# rCSL_mcasp_001 register map
Vendor: Texas Instruments
Peripheral module from a debugger description file (folder c674x).
Registers are 32-bit, read-write, reset 0x0 unless marked. A register's access mark holds for its fields unless they carry their own. Offsets are as the file gives them; lines under a group give offsets from that group; [hi:lo] are bit positions; {n}, {i} and the like mark numbered series; 'fields as' and 'values as' point back to an identical list; <NAME> marks a mode.

## MCASP — MCASP is a serial port used for audio data transfer in different formats like I2S , SPDIF..
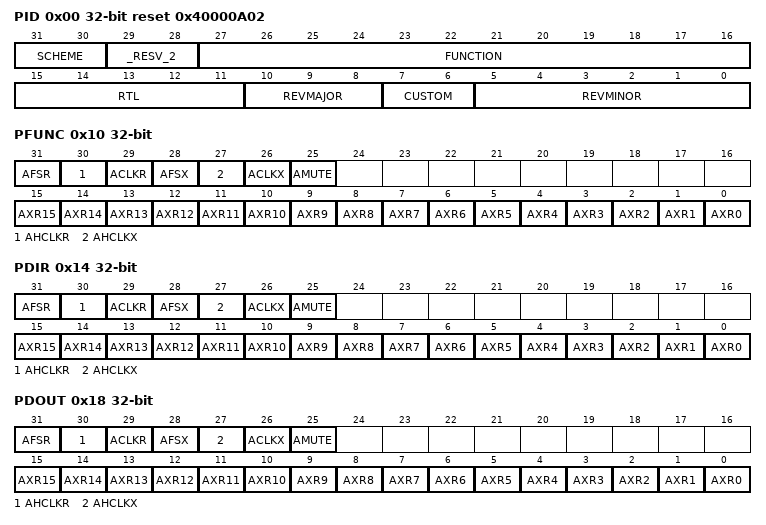
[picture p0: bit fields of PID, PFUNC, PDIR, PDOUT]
0x00 PID access not given reset 0x40000A02 (reset mask 0xF000FFFF)
  [31:30] SCHEME ro
  [29:28] _RESV_2 — (access N)
  [27:16] FUNCTION ro — McASP
  [15:11] RTL ro
  [10:8] REVMAJOR ro
  [7:6] CUSTOM ro — non-custom
  [5:0] REVMINOR ro
0x10 PFUNC access not given
  [all] fields
    0=MCASP; 1=GPIO
  [31] AFSR rw — AFSR PFUNC 31
  [30] AHCLKR rw — AHCLKR PFUNC 30
  [29] ACLKR rw — ACLKR PFUNC 29
  [28] AFSX rw — AFSX PFUNC 28
  [27] AHCLKX rw — AHCLKX PFUNC 27
  [26] ACLKX rw — ACLKX PFUNC 26
  [25] AMUTE rw — AMUTE PFUNC 25
  [n] AXR{n} rw (n=0..15) — AXR PFUNC BIT {n}
0x14 PDIR access not given
  [all] fields
    0=INPUT; 1=OUTPUT
  [31] AFSR rw — AFSR PDIR 31
  [30] AHCLKR rw — AHCLKR PDIR 30
  [29] ACLKR rw — ACLKR PDIR 29
  [28] AFSX rw — AFSX PDIR 28
  [27] AHCLKX rw — AHCLKX PDIR 27
  [26] ACLKX rw — ACLKX PDIR 26
  [25] AMUTE rw — AMUTE PDIR 25
  [n] AXR{n} rw (n=0..15) — AXR PDIR BIT {n}
0x18 PDOUT access not given
  [all] fields
    0=DRV0; 1=DRV1
  [31] AFSR rw — AFSR PDOUT 31
  [30] AHCLKR rw — AHCLKR PDOUT 30
  [29] ACLKR rw — ACLKR PDOUT 29
  [28] AFSX rw — AFSX PDOUT 28
  [27] AHCLKX rw — AHCLKX PDOUT 27
  [26] ACLKX rw — ACLKX PDOUT 26
  [25] AMUTE rw — AMUTE PDOUT 25
  [n] AXR{n} rw (n=0..15) — AXR PDOUT BIT {n}
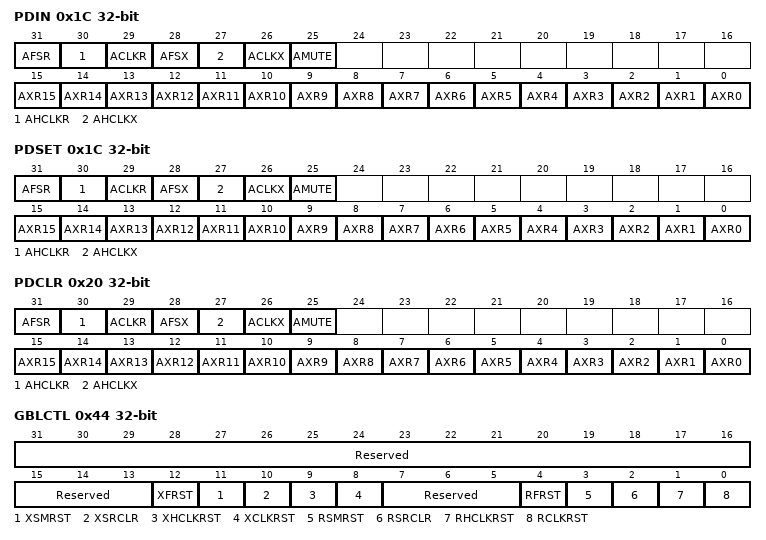
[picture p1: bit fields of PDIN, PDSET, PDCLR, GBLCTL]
0x1C PDIN access not given — The pin data input register (PDIN) holds the I/O pin state of each of the McASP pins. PDIN allows the actual value of the pin to be read, regardless of the state of PFUNC and PDIR.
  [all] fields
    0=LOW; 1=HIGH
  [31] AFSR rw — AFSR PDIN 31
  [30] AHCLKR rw — AHCLKR PDIN 30
  [29] ACLKR rw — ACLKR PDIN 29
  [28] AFSX rw — AFSX PDIN 28
  [27] AHCLKX rw — AHCLKX PDIN 27
  [26] ACLKX rw — ACLKX PDIN 26
  [25] AMUTE rw — AMUTE PDIN 25
  [n] AXR{n} rw (n=0..15) — AXR PDIN BIT {n}
0x1C PDSET access not given — The pin data set register (PDSET) is an alias of the pin data output register (PDOUT) for writes only. Writing a 1 to the PDSET bit sets the corresponding bit in PDOUT and, if PFUNC = 1 (GPIO function) and PDIR = 1 (output), drives a logic high on the pin.
  [all] fields
    0=NOEFFECT; 1=SET
  [31] AFSR rw — AFSR PDSET 31
  [30] AHCLKR rw — AHCLKR PDSET 30
  [29] ACLKR rw — ACLKR PDSET 29
  [28] AFSX rw — AFSX PDSET 28
  [27] AHCLKX rw — AHCLKX PDSET 27
  [26] ACLKX rw — ACLKX PDSET 26
  [25] AMUTE rw — AMUTE PDSET 25
  [n] AXR{n} rw (n=0..15) — AXR PDSET BIT {n}
0x20 PDCLR access not given — The pin data clear register (PDCLR) is an alias of the pin data output register (PDOUT) for writes only. Writing a 1 to the PDCLR bit clears the corresponding bit in PDOUT and, if PFUNC = 1 (GPIO function) and PDIR = 1 (output), drives a logic low on the pin.
  [all] fields
    0=NOEFFECT; 1=CLEAR
  [31] AFSR rw — AFSR PDCLR 31
  [30] AHCLKR rw — AHCLKR PDCLR 30
  [29] ACLKR rw — ACLKR PDCLR 29
  [28] AFSX rw — AFSX PDCLR 28
  [27] AHCLKX rw — AHCLKX PDCLR 27
  [26] ACLKX rw — ACLKX PDCLR 26
  [25] AMUTE rw — AMUTE PDCLR 25
  [n] AXR{n} rw (n=0..15) — AXR PDCLR BIT {n}
0x44 GBLCTL access not given
  [31:13] Reserved — (access N)
  [12] XFRST rw — Frame sync generator reset
    0=RESET; 1=ACTIVE
  [11] XSMRST rw — XMT state machine reset
    0=RESET; 1=ACTIVE
  [10] XSRCLR rw — XMT serializer clear
    0=CLEAR; 1=ACTIVE
  [9] XHCLKRST rw — XMT High Freq. clk Divider
    0=RESET; 1=ACTIVE
  [8] XCLKRST rw — XMT clock divder reset
    0=RESET; 1=ACTIVE
  [7:5] Reserved — (access N)
  [4] RFRST rw — Frame sync generator reset
    0=RESET; 1=ACTIVE
  [3] RSMRST rw — RCV state machine reset
    0=RESET; 1=ACTIVE
  [2] RSRCLR rw — RCV serializer clear
    0=CLEAR; 1=ACTIVE
  [1] RHCLKRST rw — RCV High Freq. clk Divider
    0=RESET; 1=ACTIVE
  [0] RCLKRST rw — RCV clock divder reset
    0=RESET; 1=ACTIVE
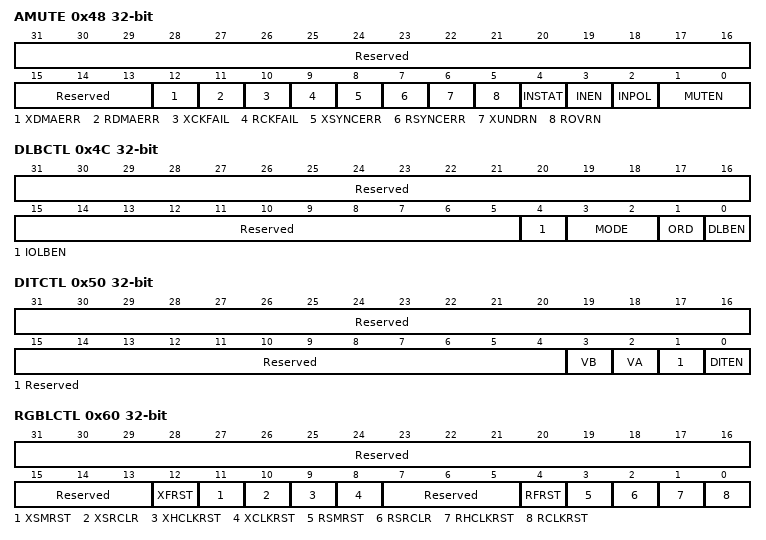
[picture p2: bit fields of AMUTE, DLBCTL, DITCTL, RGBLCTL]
0x48 AMUTE access not given
  [31:13] Reserved — (access N)
  [12] XDMAERR rw — MUTETXDMAERR occur
    0=DISABLE; 1=ENABLE
  [11] RDMAERR rw — MUTERXDMAERR occur
    0=DISABLE; 1=ENABLE
  [10] XCKFAIL rw — XMT bad clock
    0=DISABLE; 1=ENABLE
  [9] RCKFAIL rw — RCV bad clock
    0=DISABLE; 1=ENABLE
  [8] XSYNCERR rw — XMT unexpected FS
    0=DISABLE; 1=ENABLE
  [7] RSYNCERR rw — RCV unexpected FS
    0=DISABLE; 1=ENABLE
  [6] XUNDRN rw — XMT underrun occurs
    0=DISABLE; 1=ENABLE
  [5] ROVRN rw — RCV overun occurs
    0=DISABLE; 1=ENABLE
  [4] INSTAT ro — status of mute in pin
    0=INACTIVE; 1=ACTIVE
  [3] INEN rw — drive AMUTE active on mute in active
    0=DISABLE; 1=ENABLE
  [2] INPOL rw — Mute input polarity
    0=ACTHIGH; 1=ACTLOW
  [1:0] MUTEN rw — AMUTE pin enable
    0=DISABLE; 1=ERRHIGH; 2=ERRLOW
0x4C DLBCTL access not given
  [31:5] Reserved — (access N)
  [4] IOLBEN rw — IO loopback enable
    0=DISABLE; 1=ENABLE
  [3:2] MODE rw — Loop back clock source generator
    1=XMTCLK
  [1] ORD rw — Loopback order
    0=XMTODD; 1=XMTEVEN
  [0] DLBEN rw — Loop back mode
    0=DISABLE; 1=ENABLE
0x50 DITCTL access not given
  [31:4] Reserved — (access N)
  [3] VB rw — Valib bit for odd TDM
    0=ZERO; 1=ONE
  [2] VA rw — Valib bit for even TDM
    0=ZERO; 1=ONE
  [1] Reserved — (access N)
  [0] DITEN rw — XMT DIT Mode Enable
    0=DISABLE; 1=ENABLE
0x60 RGBLCTL access not given
  [31:13] Reserved — (access N)
  [12] XFRST ro — Frame sync generator reset
    0=RESET; 1=ACTIVE
  [11] XSMRST ro — XMT state machine reset
    0=RESET; 1=ACTIVE
  [10] XSRCLR ro — XMT serializer clear
    0=CLEAR; 1=ACTIVE
  [9] XHCLKRST ro — XMT High Freq. clk Divider
    0=RESET; 1=ACTIVE
  [8] XCLKRST ro — XMT clock divder reset
    0=RESET; 1=ACTIVE
  [7:5] Reserved — (access N)
  [4] RFRST rw — Frame sync generator reset
    0=RESET; 1=ACTIVE
  [3] RSMRST rw — RCV state machine reset
    0=RESET; 1=ACTIVE
  [2] RSRCLR rw — RCV serializer clear
    0=CLEAR; 1=ACTIVE
  [1] RHCLKRST rw — RCV High Freq. clk Divider
    0=RESET; 1=ACTIVE
  [0] RCLKRST rw — RCV clock divder reset
    0=RESET; 1=ACTIVE
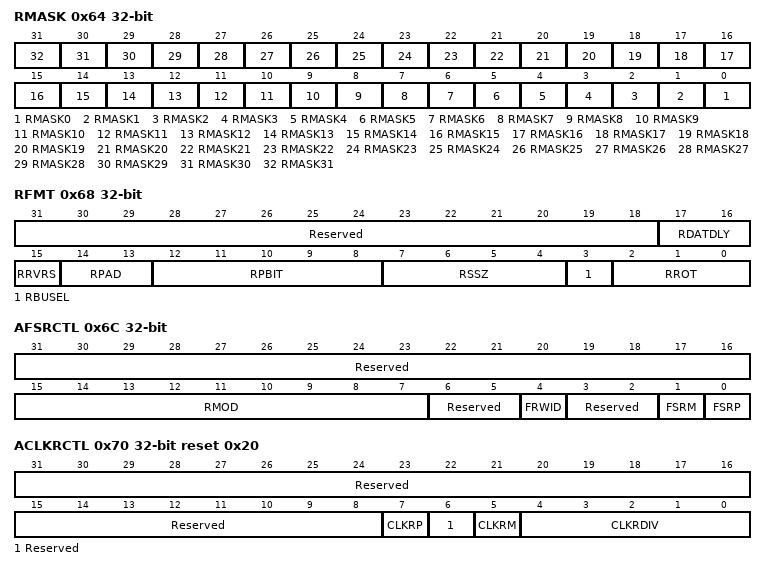
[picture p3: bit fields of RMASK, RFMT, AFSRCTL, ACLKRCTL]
0x64 RMASK
  [all] fields
    0=USEMASK; 1=NOMASK
  [n] RMASK{n} (n=0..31) — RMASK BIT {n}
0x68 RFMT access not given
  [31:18] Reserved — (access N)
  [17:16] RDATDLY rw — RCV Frame sync delay
    0=0BIT (0 Bit delay); 1=1BIT (1 Bit delay); 2=2BIT (2 Bit delay)
  [15] RRVRS rw — RCV serial stream bit order
    0=LSBFIRST; 1=MSBFIRST
  [14:13] RPAD rw — Pad value
    0=ZERO; 1=ONE; 2=RPBIT
  [12:8] RPBIT rw — Pad bit position
  [7:4] RSSZ rw — RCV slot Size
  [3] RBUSEL rw — Write to RBUF using CPU/DMA
    0=VBUSP (DMA port access); 1=VBUS (CPU port Access)
  [2:0] RROT rw — Right Rotate Value
    0=NONE; 1=4BITS; 2=8BITS; 3=12BITS; 4=16BITS; 5=20BITS; 6=24BITS; 7=28BITS
0x6C AFSRCTL access not given
  [31:16] Reserved — (access N)
  [15:7] RMOD rw — RCV Frame sync mode
    0=BURST; 2=I2S
  [6:5] Reserved — (access N)
  [4] FRWID rw — RCV Frame sync Duration
    0=BIT; 1=WORD
  [3:2] Reserved — (access N)
  [1] FSRM rw — RCV frame sync External
    0=EXTERNAL; 1=INTERNAL
  [0] FSRP rw — RCV Frame sync Polarity
    0=RISINGEDGE; 1=FALLINGEDGE
0x70 ACLKRCTL access not given reset 0x20
  [31:8] Reserved — (access N)
  [7] CLKRP rw — RCV Clock Polarity
    0=FALLINGEDGE; 1=RISINGEDGE
  [6] Reserved — (access N)
  [5] CLKRM rw — RCV clock source
    0=EXTERNAL; 1=INTERNAL
  [4:0] CLKRDIV rw — RCV clock devide ratio
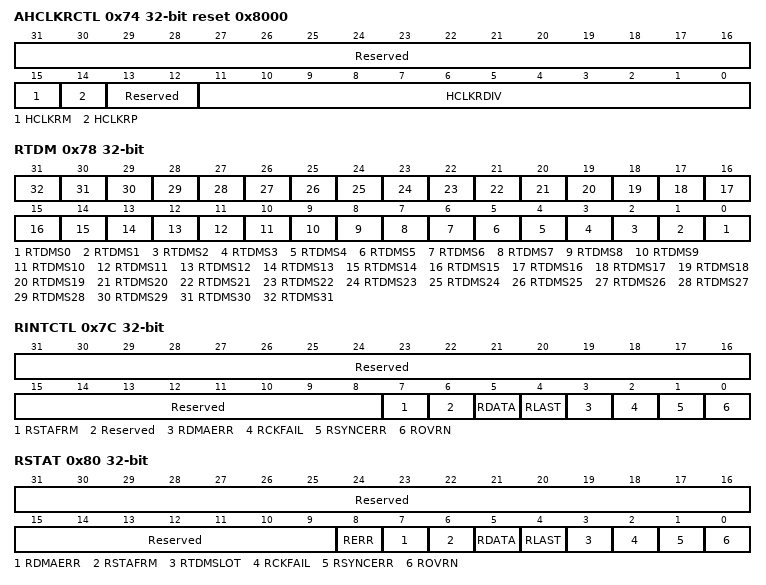
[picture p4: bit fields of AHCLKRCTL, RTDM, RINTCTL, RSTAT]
0x74 AHCLKRCTL access not given reset 0x8000
  [31:16] Reserved — (access N)
  [15] HCLKRM rw — High Freq. RCV clock Source
    0=EXTERNAL; 1=INTERNAL
  [14] HCLKRP rw — High Freq. clock Polarity Before diviser
    0=NOTINVERTED; 1=INVERTED
  [13:12] Reserved — (access N)
  [11:0] HCLKRDIV rw — RCV clock Divide Ratio
0x78 RTDM
  [all] fields
    0=INACTIVE; 1=ACTIVE
  [n] RTDMS{n} (n=0..31) — RCV mode during TDM time slot {n}
0x7C RINTCTL access not given
  [31:8] Reserved — (access N)
  [7] RSTAFRM rw — RCV Start of Frame Interrupt
    0=DISABLE; 1=ENABLE
  [6] Reserved — (access N)
  [5] RDATA rw — RCV Data Interrupt
    0=DISABLE; 1=ENABLE
  [4] RLAST rw — RCV Last Slot Interrupt
    0=DISABLE; 1=ENABLE
  [3] RDMAERR rw — RCV DMA Bus Error
    0=DISABLE; 1=ENABLE
  [2] RCKFAIL rw — Bad Clock Interrupt
    0=DISABLE; 1=ENABLE
  [1] RSYNCERR rw — RCV Unexpected FSR Interrupt
    0=DISABLE; 1=ENABLE
  [0] ROVRN rw — RCV Underrun Flag
    0=DISABLE; 1=ENABLE
0x80 RSTAT access not given
  [31:9] Reserved — (access N)
  [8] RERR — RCV Error
    0=NOERROR; 1=ERROR
  [7] RDMAERR rw — RCV DMA bus error
    0=NOERROR; 1=ERROR
  [6] RSTAFRM rw — Start of Frame-RCV
    0=NO; 1=YES
  [5] RDATA rw — Data Ready Flag
    0=NO; 1=YES
  [4] RLAST rw — Last Slot Interrupt Flag
    0=NO; 1=YES
  [3] RTDMSLOT rw — EvenOdd Slot
    0=ODD; 1=EVEN
  [2] RCKFAIL rw — Bad Transmit Flag
    0=NO; 1=YES
  [1] RSYNCERR rw — Unexpected RCV Frame sync flag
    0=NO; 1=YES
  [0] ROVRN rw — RCV Underrun Flag
    0=NO; 1=YES
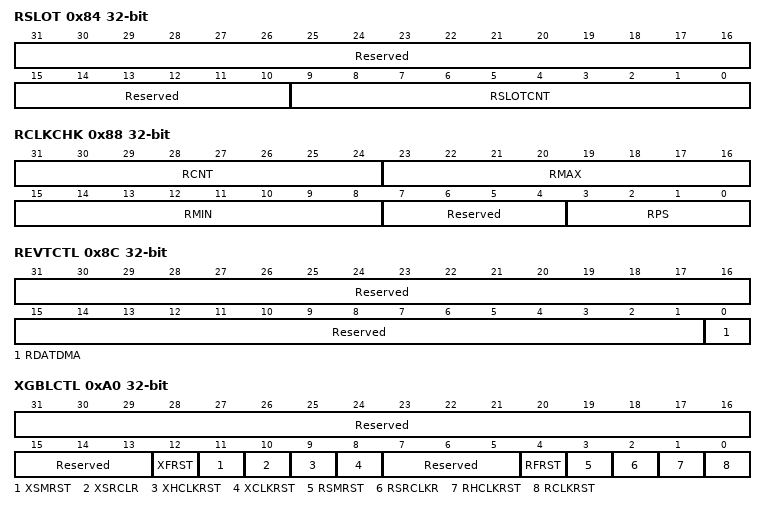
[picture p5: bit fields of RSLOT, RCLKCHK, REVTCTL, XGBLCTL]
0x84 RSLOT access not given
  [31:10] Reserved — (access N)
  [9:0] RSLOTCNT ro — Current RCV time slot count
0x88 RCLKCHK access not given
  [31:24] RCNT ro — RCV clock count value
  [23:16] RMAX rw — RCV clock maximum boundary
  [15:8] RMIN rw — RCV clock minimum boundary
  [7:4] Reserved — (access N)
  [3:0] RPS rw — RCV clock check prescaler
    0=DIVBY1; 1=DIVBY2; 2=DIVBY4; 3=DIVBY8; 4=DIVBY16; 5=DIVBY32; 6=DIVBY64; 7=DIVBY128; 8=DIVBY256
0x8C REVTCTL access not given
  [31:1] Reserved — (access N)
  [0] RDATDMA rw — RCV data DMA request
    0=ENABLE (Enable DMA event); 1=RSV (Reserved)
0xA0 XGBLCTL access not given
  [31:13] Reserved — (access N)
  [12] XFRST rw — Frame sync generator reset
    0=RESET; 1=ACTIVE
  [11] XSMRST rw — XMT state machine reset
    0=RESET; 1=ACTIVE
  [10] XSRCLR rw — XMT serializer clear
    0=CLEAR; 1=ACTIVE
  [9] XHCLKRST rw — XMT High Freq. clk Divider
    0=RESET; 1=ACTIVE
  [8] XCLKRST rw — XMT clock divder reset
    0=RESET; 1=ACTIVE
  [7:5] Reserved — (access N)
  [4] RFRST ro — Frame sync generator reset
    0=RESET; 1=ACTIVE
  [3] RSMRST ro — RCV state machine reset
    0=RESET; 1=ACTIVE
  [2] RSRCLKR ro — RCV serializer clear
    0=CLEAR; 1=ACTIVE
  [1] RHCLKRST ro — RCV High Freq. clk Divider
    0=RESET; 1=ACTIVE
  [0] RCLKRST ro — RCV clock divder reset
    0=RESET; 1=ACTIVE
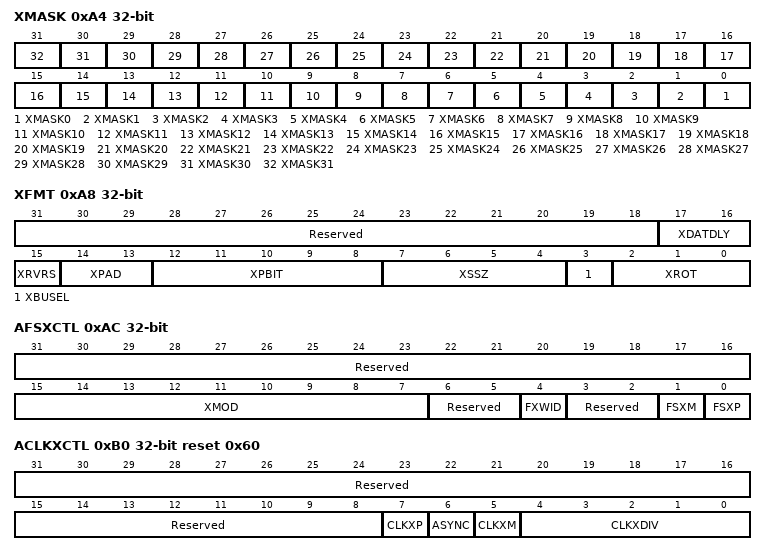
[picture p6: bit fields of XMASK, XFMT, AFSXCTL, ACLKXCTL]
0xA4 XMASK
  [all] fields
    0=USEMASK; 1=NOMASK
  [n] XMASK{n} (n=0..31) — XMASK BIT {n}
0xA8 XFMT access not given
  [31:18] Reserved — (access N)
  [17:16] XDATDLY rw — XMT Frame sync delay
    values as RFMT.RDATDLY
  [15] XRVRS rw — XMT serial stream bit order
    0=LSBFIRST; 1=MSBFIRST
  [14:13] XPAD rw — Pad value
    0=ZERO; 1=ONE; 2=XPBIT
  [12:8] XPBIT rw — Pad bit position
  [7:4] XSSZ rw — XMT slot Size
  [3] XBUSEL rw — Write to XBUF using CPU/DMA
    0=VBUSP (DMA port access); 1=VBUS (CPU port Access)
  [2:0] XROT rw — Right Rotate Value
    values as RFMT.RROT
0xAC AFSXCTL access not given
  [31:16] Reserved — (access N)
  [15:7] XMOD rw — XMT Frame sync mode
    0=BURST; 2=I2S
  [6:5] Reserved — (access N)
  [4] FXWID rw — XMT Frame sync Duration
    0=BIT; 1=WORD
  [3:2] Reserved — (access N)
  [1] FSXM rw — XMT frame sync External
    0=EXTERNAL; 1=INTERNAL
  [0] FSXP rw — XMT Frame sync Polarity
    0=RISINGEDGE; 1=FALLINGEDGE
0xB0 ACLKXCTL access not given reset 0x60
  [31:8] Reserved — (access N)
  [7] CLKXP rw — XMT Clock Polarity
    0=RISINGEDGE; 1=FALLINGEDGE
  [6] ASYNC rw — XMT/RCV operation sync /Async
    0=SYNC; 1=ASYNC
  [5] CLKXM rw — XMT clock source
    0=EXTERNAL; 1=INTERNAL
  [4:0] CLKXDIV rw — XMT clock devide ratio
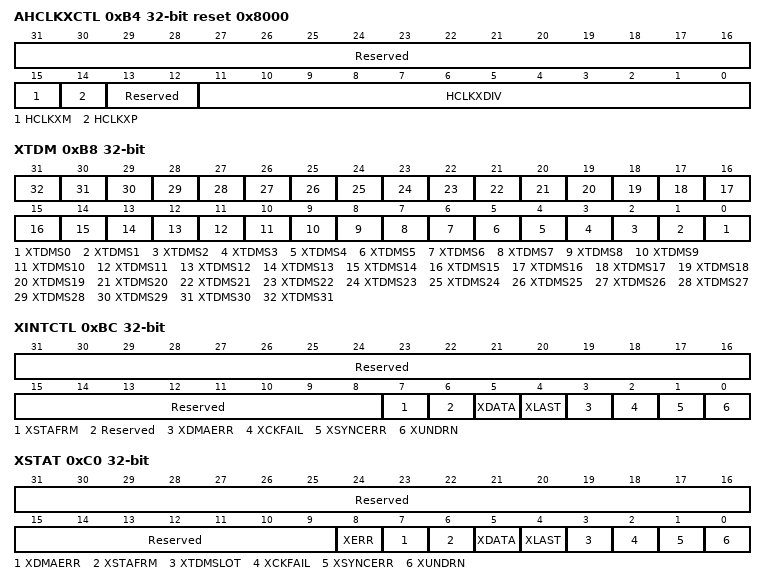
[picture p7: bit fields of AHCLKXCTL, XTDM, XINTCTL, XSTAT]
0xB4 AHCLKXCTL access not given reset 0x8000
  [31:16] Reserved — (access N)
  [15] HCLKXM rw — High Freq. XMT clock Source
    0=EXTERNAL; 1=INTERNAL
  [14] HCLKXP rw — High Freq. clock Polarity Before diviser
    0=NOTINVERTED; 1=INVERTED
  [13:12] Reserved — (access N)
  [11:0] HCLKXDIV rw — XMT clock Divide Ratio
0xB8 XTDM
  [all] fields
    0=INACTIVE; 1=ACTIVE
  [n] XTDMS{n} (n=0..31) — XMT mode during TDM time slot {n}
0xBC XINTCTL access not given
  [31:8] Reserved — (access N)
  [7] XSTAFRM rw — XMT Start of Frame Interrupt
    0=DISABLE; 1=ENABLE
  [6] Reserved — (access N)
  [5] XDATA rw — XMT Data Interrupt
    0=DISABLE; 1=ENABLE
  [4] XLAST rw — XMT Last Slot Interrupt
    0=DISABLE; 1=ENABLE
  [3] XDMAERR rw — XMT DMA Bus Error
    0=DISABLE; 1=ENABLE
  [2] XCKFAIL rw — Bad Clock Interrupt
    0=DISABLE; 1=ENABLE
  [1] XSYNCERR rw — XMT Unexpected FSR Interrupt
    0=DISABLE; 1=ENABLE
  [0] XUNDRN rw — XMT Underrun Interrupt
    0=DISABLE; 1=ENABLE
0xC0 XSTAT access not given
  [31:9] Reserved — (access N)
  [8] XERR — XMT Error
    0=NOERROR; 1=ERROR
  [7] XDMAERR rw — XMT DMA bus error
    0=NOERROR; 1=ERROR
  [6] XSTAFRM rw — Start of Frame-XMT
    0=NO; 1=YES
  [5] XDATA rw — Data Ready Flag
    0=NO; 1=YES
  [4] XLAST rw — Last Slot Interrupt Flag
    0=NO; 1=YES
  [3] XTDMSLOT rw — EvenOdd Slot
    0=ODD; 1=EVEN
  [2] XCKFAIL rw — Bad Transmit Flag
    0=NO; 1=YES
  [1] XSYNCERR rw — Unexpected XMT Frame sync flag
    0=NO; 1=YES
  [0] XUNDRN rw — XMT Underrun Flag
    0=NO; 1=YES
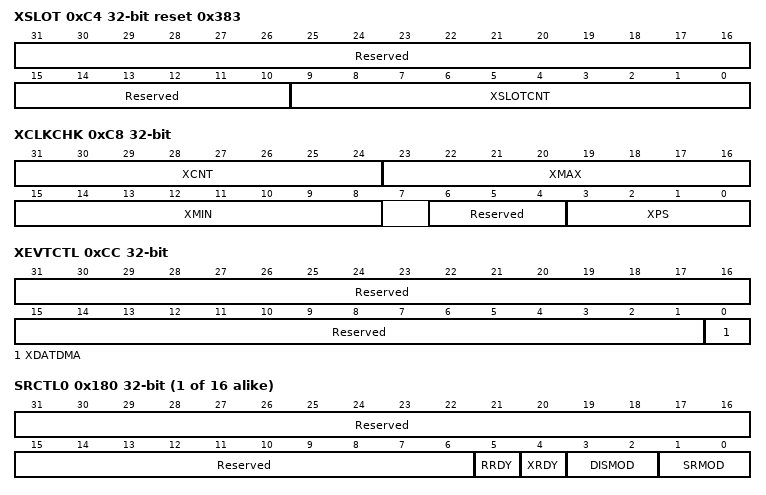
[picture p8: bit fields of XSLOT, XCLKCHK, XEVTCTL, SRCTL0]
0xC4 XSLOT access not given reset 0x383
  [31:10] Reserved — (access N)
  [9:0] XSLOTCNT ro — Current XMT time slot count
0xC8 XCLKCHK access not given
  [31:24] XCNT ro — XMT clock count value
  [23:16] XMAX rw — XMT clock maximum boundary
  [15:8] XMIN rw — XMT clock minimum boundary
  [6:4] Reserved — (access N)
  [3:0] XPS rw — XMT clock check prescaler
    values as RCLKCHK.RPS
0xCC XEVTCTL access not given
  [31:1] Reserved — (access N)
  [0] XDATDMA rw — XMT data DMA request
    0=ENABLE (Enable DMA events); 1=RSV (Reserved)
0x100 DITCSRA0
  [31:0] DITCSRA0 — Left (Even TDM slot ) Channel status
0x104 DITCSRA1
  [31:0] DITCSRA1 — Left (Even TDM slot ) Channel status
0x108 DITCSRA2
  [31:0] DITCSRA2 — Left (Even TDM slot ) Channel status Register
0x10C DITCSRA3
  [31:0] DITCSRA3 — Left (Even TDM slot ) Channel status Register
0x110 DITCSRA4
  [31:0] DITCSRA4 — Left (Even TDM slot ) Channel status
0x114 DITCSRA5
  [31:0] DITCSRA5 — Left (Even TDM slot ) Channel status
{0x118+4i} DITCSRB{i} (i=0..5)
  [31:0] DITCSRB{i} — Right (odd TDM slot ) Channel status
{0x130+4i} DITUDRA{i} (i=0..5)
  [31:0] DITUDRA{i} — Left (Even TDM slot ) User Data
{0x148+4i} DITUDRB{i} (i=0..5)
  [31:0] DITUDRB{i} — Right (odd TDM slot ) User Data
{0x180+4i} SRCTL{i} access not given (i=0..15)
  [31:6] Reserved — (access N)
  [5] RRDY ro — Receive buffer ready
    0=EMPTY; 1=DATA
  [4] XRDY ro — Transmit buffer ready
    0=DATA; 1=EMPTY
  [3:2] DISMOD rw — Serializer drive state
    0=3STATE (Tri state); 1=RSV (Reserved); 2=LOW (Drive pin low); 3=HIGH (Drive pin high)
  [1:0] SRMOD rw — Serializer Mode
    0=INACTIVE (InActive mode); 1=XMT (Transmit mode); 2=RCV (Receive mode)
{0x200+4i} XBUF{i} (i=0..15)
  [31:0] XBUF{i} — Transmit Buffer {i}
{0x280+4i} RBUF{i} (i=0..15)
  [31:0] RBUF{i} — Receive Buffer {i}
